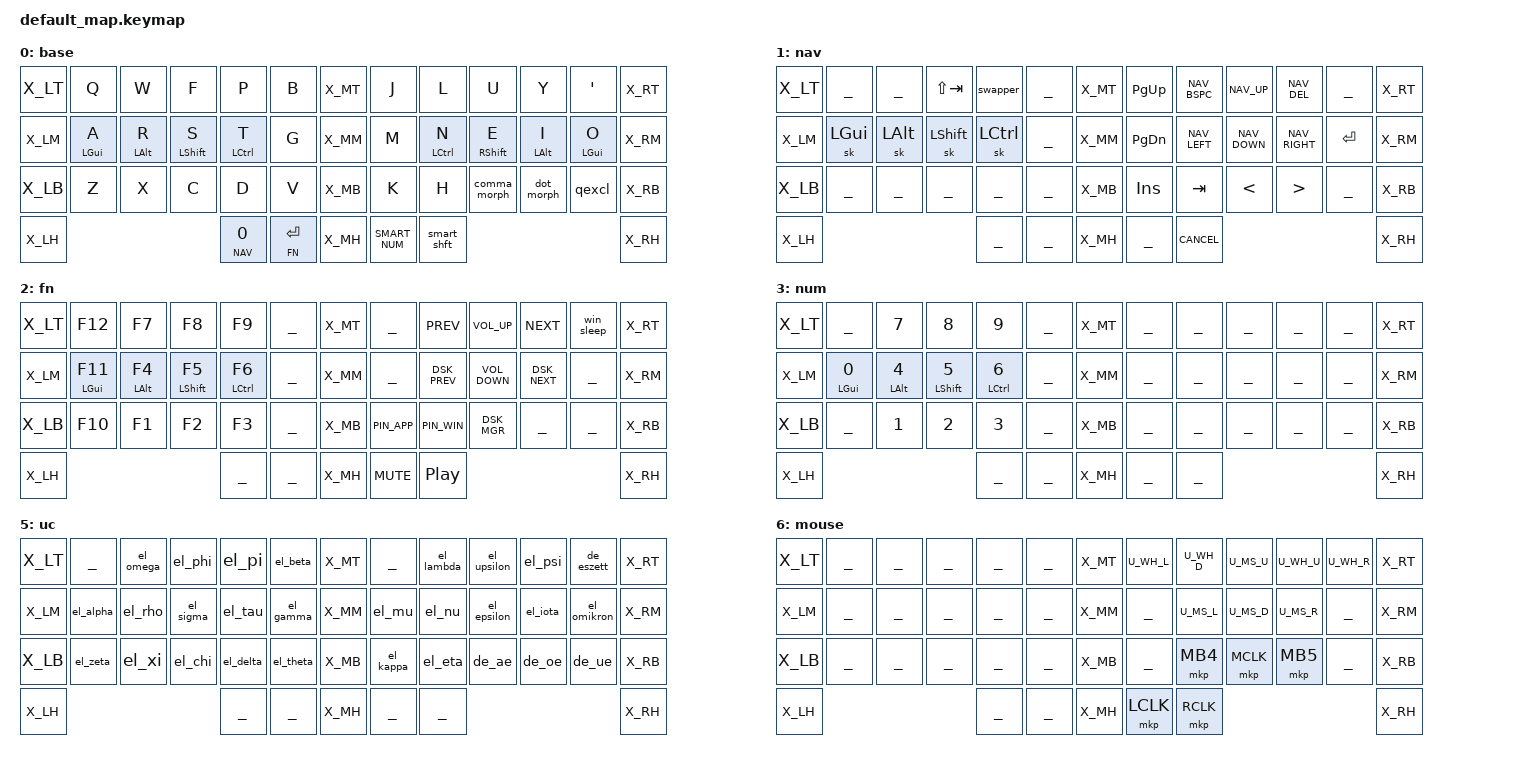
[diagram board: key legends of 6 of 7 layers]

ZMK_LAYER(base,
//╭──────╮ ╭─────────────┬─────────────┬─────────────┬─────────────┬─────────────╮ ╭──────╮ ╭─────────────┬─────────────┬─────────────┬─────────────┬─────────────╮ ╭──────╮
    X_LT     &kp Q         &kp W         &kp F         &kp P         &kp B           X_MT     &kp J         &kp L         &kp U         &kp Y         &kp SQT         X_RT
//├──────┤ ├─────────────┼─────────────┼─────────────┼─────────────┼─────────────┤ ├──────┤ ├─────────────┼─────────────┼─────────────┼─────────────┼─────────────┤ ├──────┤
    X_LM     &hml LGUI A   &hml LALT R   &hml LSHFT S  &hml LCTRL T  &kp G           X_MM     &kp M         &hmr LCTRL N  &hmr RSHFT E  &hmr LALT I   &hmr LGUI O     X_RM
//├──────┤ ├─────────────┼─────────────┼─────────────┼─────────────┼─────────────┤ ├──────┤ ├─────────────┼─────────────┼─────────────┼─────────────┼─────────────┤ ├──────┤
    X_LB     &kp Z         &kp X         &kp C         &kp D         &kp V           X_MB     &kp K         &kp H         &comma_morph  &dot_morph    &qexcl          X_RB
//├──────┤ ╰─────────────┼─────────────┴─────────────┼─────────────┼─────────────┤ ├──────┤ ├─────────────┼─────────────┼─────────────┴───────────────────────────╯ ├──────┤
    X_LH                                               &lt_spc NAV 0 &lt FN RET      X_MH     SMART_NUM     &smart_shft                                               X_RH
//╰──────╯                                           ╰─────────────┴─────────────╯ ╰──────╯ ╰─────────────┴─────────────╯                                           ╰──────╯
)

ZMK_LAYER(nav,
//╭──────╮ ╭─────────────┬─────────────┬─────────────┬─────────────┬─────────────╮ ╭──────╮ ╭─────────────┬─────────────┬─────────────┬─────────────┬─────────────╮ ╭──────╮
    X_LT     ___           ___           &kp LS(TAB)   &swapper      ___             X_MT     &kp PG_UP     NAV_BSPC      NAV_UP        NAV_DEL       ___             X_RT
//├──────┤ ├─────────────┼─────────────┼─────────────┼─────────────┼─────────────┤ ├──────┤ ├─────────────┼─────────────┼─────────────┼─────────────┼─────────────┤ ├──────┤
    X_LM     &sk LGUI      &sk LALT      &sk LSHFT     &sk LCTRL     ___             X_MM     &kp PG_DN     NAV_LEFT      NAV_DOWN      NAV_RIGHT     &kp RET         X_RM
//├──────┤ ├─────────────┼─────────────┼─────────────┼─────────────┼─────────────┤ ├──────┤ ├─────────────┼─────────────┼─────────────┼─────────────┼─────────────┤ ├──────┤
    X_LB     ___           ___           ___           ___           ___             X_MB     &kp INS       &kp TAB       &kp LT        &kp GT        ___             X_RB
//├──────┤ ╰─────────────┼─────────────┴─────────────┼─────────────┼─────────────┤ ├──────┤ ├─────────────┼─────────────┼─────────────┴───────────────────────────╯ ├──────┤
    X_LH                                               ___           ___             X_MH     ___           CANCEL                                                    X_RH
//╰──────╯                                           ╰─────────────┴─────────────╯ ╰──────╯ ╰─────────────┴─────────────╯                                           ╰──────╯
)

ZMK_LAYER(fn,
//╭──────╮ ╭─────────────┬─────────────┬─────────────┬─────────────┬─────────────╮ ╭──────╮ ╭─────────────┬─────────────┬─────────────┬─────────────┬─────────────╮ ╭──────╮
    X_LT     &kp F12       &kp F7        &kp F8        &kp F9        ___             X_MT     ___           &kp C_PREV    &kp C_VOL_UP  &kp C_NEXT    &win_sleep      X_RT
//├──────┤ ├─────────────┼─────────────┼─────────────┼─────────────┼─────────────┤ ├──────┤ ├─────────────┼─────────────┼─────────────┼─────────────┼─────────────┤ ├──────┤
    X_LM     &hml LGUI F11 &hml LALT F4  &hml LSHFT F5 &hml LCTRL F6 ___             X_MM     ___           DSK_PREV      VOL_DOWN      DSK_NEXT      ___             X_RM
//├──────┤ ├─────────────┼─────────────┼─────────────┼─────────────┼─────────────┤ ├──────┤ ├─────────────┼─────────────┼─────────────┼─────────────┼─────────────┤ ├──────┤
    X_LB     &kp F10       &kp F1        &kp F2        &kp F3        ___             X_MB     PIN_APP       PIN_WIN       DSK_MGR       ___           ___             X_RB
//├──────┤ ╰─────────────┼─────────────┴─────────────┼─────────────┼─────────────┤ ├──────┤ ├─────────────┼─────────────┼─────────────┴───────────────────────────╯ ├──────┤
    X_LH                                               ___           ___             X_MH     &kp C_MUTE    &kp C_PP                                                  X_RH
//╰──────╯                                           ╰─────────────┴─────────────╯ ╰──────╯ ╰─────────────┴─────────────╯                                           ╰──────╯
)

ZMK_LAYER(num,
//╭──────╮ ╭─────────────┬─────────────┬─────────────┬─────────────┬─────────────╮ ╭──────╮ ╭─────────────┬─────────────┬─────────────┬─────────────┬─────────────╮ ╭──────╮
    X_LT     ___           &kp N7        &kp N8        &kp N9        ___             X_MT     ___           ___           ___           ___           ___             X_RT
//├──────┤ ├─────────────┼─────────────┼─────────────┼─────────────┼─────────────┤ ├──────┤ ├─────────────┼─────────────┼─────────────┼─────────────┼─────────────┤ ├──────┤
    X_LM     &hml LGUI N0  &hml LALT N4  &hml LSHFT N5 &hml LCTRL N6 ___             X_MM     ___           ___           ___           ___           ___             X_RM
//├──────┤ ├─────────────┼─────────────┼─────────────┼─────────────┼─────────────┤ ├──────┤ ├─────────────┼─────────────┼─────────────┼─────────────┼─────────────┤ ├──────┤
    X_LB     ___           &kp N1        &kp N2        &kp N3        ___             X_MB     ___           ___           ___           ___           ___             X_RB
//├──────┤ ╰─────────────┼─────────────┴─────────────┼─────────────┼─────────────┤ ├──────┤ ├─────────────┼─────────────┼─────────────┴───────────────────────────╯ ├──────┤
    X_LH                                               ___           ___             X_MH     ___           ___                                                       X_RH
//╰──────╯                                           ╰─────────────┴─────────────╯ ╰──────╯ ╰─────────────┴─────────────╯                                           ╰──────╯
)

ZMK_LAYER(sys,
//╭──────╮ ╭─────────────┬─────────────┬─────────────┬─────────────┬─────────────╮ ╭──────╮ ╭─────────────┬─────────────┬─────────────┬─────────────┬─────────────╮ ╭──────╮
    X_LT                                _BT_SEL_KEYS_                                X_MT     ___           ___           ___           ___           ___             X_RT
//├──────┤ ├─────────────┼─────────────┼─────────────┼─────────────┼─────────────┤ ├──────┤ ├─────────────┼─────────────┼─────────────┼─────────────┼─────────────┤ ├──────┤
    X_LM     ___           ___           ___           ___           &bootloader     X_MM     &bootloader   ___           ___           ___           ___             X_RM
//├──────┤ ├─────────────┼─────────────┼─────────────┼─────────────┼─────────────┤ ├──────┤ ├─────────────┼─────────────┼─────────────┼─────────────┼─────────────┤ ├──────┤
    X_LB     ___           ___           ___           ___           &sys_reset      X_MB     &sys_reset    ___           ___           ___           ___             X_RB
//├──────┤ ╰─────────────┼─────────────┴─────────────┼─────────────┼─────────────┤ ├──────┤ ├─────────────┼─────────────┼─────────────┴───────────────────────────╯ ├──────┤
    X_LH                                               ___           ___             X_MH     ___           ___                                                       X_RH
//╰──────╯                                           ╰─────────────┴─────────────╯ ╰──────╯ ╰─────────────┴─────────────╯                                           ╰──────╯
)

ZMK_LAYER(uc,
//╭──────╮ ╭─────────────┬─────────────┬─────────────┬─────────────┬─────────────╮ ╭──────╮ ╭─────────────┬─────────────┬─────────────┬─────────────┬─────────────╮ ╭──────╮
    X_LT     ___           &el_omega     &el_phi       &el_pi        &el_beta        X_MT     ___           &el_lambda    &el_upsilon   &el_psi       &de_eszett      X_RT
//├──────┤ ├─────────────┼─────────────┼─────────────┼─────────────┼─────────────┤ ├──────┤ ├─────────────┼─────────────┼─────────────┼─────────────┼─────────────┤ ├──────┤
    X_LM     &el_alpha     &el_rho       &el_sigma     &el_tau       &el_gamma       X_MM     &el_mu        &el_nu        &el_epsilon   &el_iota      &el_omikron     X_RM
//├──────┤ ├─────────────┼─────────────┼─────────────┼─────────────┼─────────────┤ ├──────┤ ├─────────────┼─────────────┼─────────────┼─────────────┼─────────────┤ ├──────┤
    X_LB     &el_zeta      &el_xi        &el_chi       &el_delta     &el_theta       X_MB     &el_kappa     &el_eta       &de_ae        &de_oe        &de_ue          X_RB
//├──────┤ ╰─────────────┼─────────────┴─────────────┼─────────────┼─────────────┤ ├──────┤ ├─────────────┼─────────────┼─────────────┴───────────────────────────╯ ├──────┤
    X_LH                                               ___           ___             X_MH     ___           ___                                                       X_RH
//╰──────╯                                           ╰─────────────┴─────────────╯ ╰──────╯ ╰───────────────────────────╯                                           ╰──────╯
)

ZMK_LAYER(mouse,
//╭──────╮ ╭─────────────┬─────────────┬─────────────┬─────────────┬─────────────╮ ╭──────╮ ╭─────────────┬─────────────┬─────────────┬─────────────┬─────────────╮ ╭──────╮
    X_LT     ___           ___           ___           ___           ___             X_MT     U_WH_L        U_WH_D        U_MS_U         U_WH_U       U_WH_R          X_RT
//├──────┤ ├─────────────┼─────────────┼─────────────┼─────────────┼─────────────┤ ├──────┤ ├─────────────┼─────────────┼─────────────┼─────────────┼─────────────┤ ├──────┤
    X_LM     ___           ___           ___           ___           ___             X_MM     ___           U_MS_L        U_MS_D         U_MS_R       ___             X_RM
//├──────┤ ├─────────────┼─────────────┼─────────────┼─────────────┼─────────────┤ ├──────┤ ├─────────────┼─────────────┼─────────────┼─────────────┼─────────────┤ ├──────┤
    X_LB     ___           ___           ___           ___           ___             X_MB     ___           &mkp MB4      &mkp MCLK      &mkp MB5     ___             X_RB
//├──────┤ ╰─────────────┼─────────────┴─────────────┼─────────────┼─────────────┤ ├──────┤ ├─────────────┼─────────────┼─────────────┴───────────────────────────╯ ├──────┤
    X_LH                                               ___           ___             X_MH     &mkp LCLK     &mkp RCLK                                                 X_RH
//╰──────╯                                           ╰─────────────┴─────────────╯ ╰──────╯ ╰─────────────┴─────────────╯                                           ╰──────╯
)
